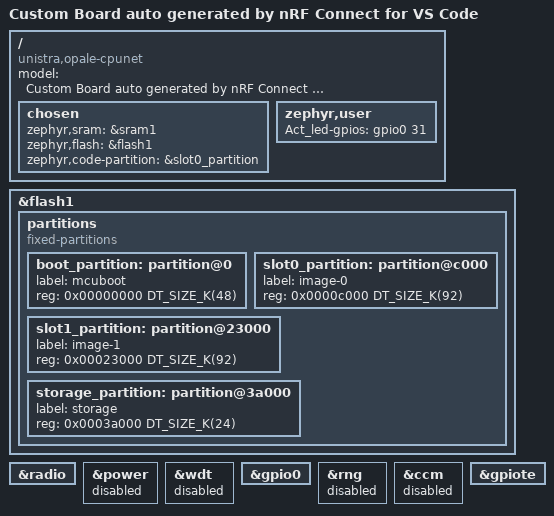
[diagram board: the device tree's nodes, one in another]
/dts-v1/;
#include <nordic/nrf5340_cpunet_qkaa.dtsi>
#include "opale-pinctrl.dtsi"

/ {
	model = "Custom Board auto generated by nRF Connect for VS Code";
	compatible = "unistra,opale-cpunet";

	chosen {
		zephyr,sram = &sram1;
		zephyr,flash = &flash1;
		zephyr,code-partition = &slot0_partition;
	};

    zephyr,user {
        Act_led-gpios = <&gpio0 31 0>;
    };
};

&flash1 {
	partitions {
		compatible = "fixed-partitions";
		#address-cells = <1>;
		#size-cells = <1>;

		boot_partition: partition@0 {
			label = "mcuboot";
			reg = <0x00000000 DT_SIZE_K(48)>;
		};

		slot0_partition: partition@c000 {
			label = "image-0";
			reg = <0x0000c000 DT_SIZE_K(92)>;
		};

		slot1_partition: partition@23000 {
			label = "image-1";
			reg = <0x00023000 DT_SIZE_K(92)>;
		};

		storage_partition: partition@3a000 {
			label = "storage";
			reg = <0x0003a000 DT_SIZE_K(24)>;
		};
	};
};

#include "opale-shared_sram.dtsi"

&radio {
    /delete-property/ ble-2mbps-supported;
    /delete-property/ ieee802154-supported;
    /delete-property/ dfe-supported;
    /delete-property/ ble-coded-phy-supported;
};

&power {
    status = "disabled";
};

&wdt {
    status = "disabled";
};

&gpio0 {
    status = "okay";
};

&rng {
    status = "disabled";
};

&ccm {
    status = "disabled";
};

&gpiote {
    status = "okay";
};
